# TLSR8258 register map
File version: 0.1
Registers are 8-bit, access not given, no defined reset value unless marked. A register's access mark holds for its fields unless they carry their own. Offsets are from the block's base; [hi:lo] are bit positions; {n}, {i} and the like mark numbered series.

## TIMER — Auto-generated from section 'timer'
Base 0x00800620
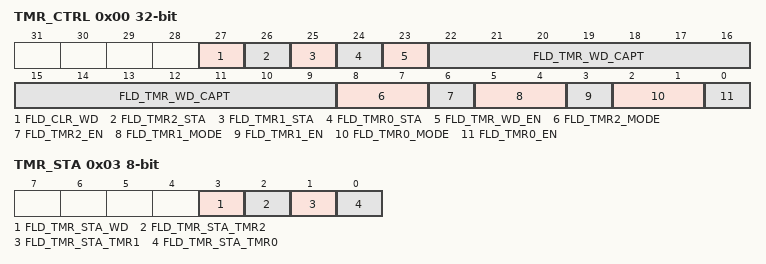
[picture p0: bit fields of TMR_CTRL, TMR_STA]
0x00 TMR_CTRL 32-bit — Auto-generated from tmr_ctrl; aliases: TMR_CTRL16, TMR_CTRL8
  [27] FLD_CLR_WD, [26] FLD_TMR2_STA, [25] FLD_TMR1_STA, [24] FLD_TMR0_STA, [23] FLD_TMR_WD_EN, [22:9] FLD_TMR_WD_CAPT, [8:7] FLD_TMR2_MODE, [6] FLD_TMR2_EN, [5:4] FLD_TMR1_MODE, [3] FLD_TMR1_EN, [2:1] FLD_TMR0_MODE, [0] FLD_TMR0_EN
0x03 TMR_STA — Auto-generated from tmr_sta
  [3] FLD_TMR_STA_WD, [2] FLD_TMR_STA_TMR2, [1] FLD_TMR_STA_TMR1, [0] FLD_TMR_STA_TMR0
{0x4+4i} TMR{i}_CAPT 32-bit (i=0..2) — Auto-generated from tmr{i}_capt
{0x10+4i} TMR{i}_TICK 32-bit (i=0..2) — Auto-generated from tmr{i}_tick

## IRQ — Auto-generated from section 'irq'
Base 0x00800640
0x00 IRQ_MASK 32-bit — Auto-generated from irq_mask
0x03 IRQ_EN — Auto-generated from irq_en
0x04 IRQ_PRI 32-bit — Auto-generated from irq_pri
0x08 IRQ_SRC 32-bit — Auto-generated from irq_src
  [31:24] FLD_IRQ_EN, [22] FLD_IRQ_GPIO_RISC1_EN, [21] FLD_IRQ_GPIO_RISC0_EN, [20] FLD_IRQ_SYSTEM_TIMER, [19] FLD_IRQ_PM_EN, [18] FLD_IRQ_GPIO_EN, [17] FLD_IRQ_USB_RST_EN, [16] FLD_IRQ_USB_250US_EN, [14] FLD_IRQ_SW_PWM_EN, [13] FLD_IRQ_ZB_RT_EN, [12] FLD_IRQ_EP_DATA_EN, [12] FLD_IRQ_IRQ4_EN, [11] FLD_IRQ_SET_INTF_EN, [10] FLD_IRQ_EP0_STA_EN, [9] FLD_IRQ_EP0_DAT_EN, [8] FLD_IRQ_EP0_SETUP_EN, [7] FLD_IRQ_HOST_CMD_EN, [7] FLD_IRQ_MIX_CMD_EN, [6] FLD_IRQ_UART_EN, [5] FLD_IRQ_DAM_FIFO_EN, [4] FLD_IRQ_DMA_EN, [3] FLD_IRQ_USB_PWDN_EN, [2] FLD_IRQ_TMR2_EN, [1] FLD_IRQ_TMR1_EN, [0] FLD_IRQ_TMR0_EN
0x0A IRQ_SRC3 — Auto-generated from irq_src3

## SYSTEM_TIMER — Auto-generated from section 'system timer'
Base 0x00800740
0x00 SYSTEM_TICK 32-bit — Auto-generated from system_tick
0x04 SYSTEM_TICK_IRQ 32-bit — Auto-generated from system_tick_irq
0x08 SYSTEM_WAKEUP_TICK 32-bit — Auto-generated from system_wakeup_tick
0x0C SYSTEM_TICK_MODE — Auto-generated from system_tick_mode
0x0F SYSTEM_TICK_CTRL — Auto-generated from system_tick_ctrl
  [1] FLD_SYSTEM_TICK_IRQ_EN, [1] FLD_SYSTEM_TICK_RUNNING, [1] FLD_SYSTEM_TICK_STOP, [0] FLD_SYSTEM_TICK_START

## PWM — Auto-generated from section 'pwm'
Base 0x00800780
0x00 PWM_ENABLE — Auto-generated from pwm_enable
0x01 PWM0_ENABLE — Auto-generated from pwm0_enable
0x02 PWM_CLK — Auto-generated from pwm_clk
0x03 PWM0_MODE — Auto-generated from pwm0_mode
0x04 PWM_INVERT — Auto-generated from pwm_invert
0x05 PWM_N_INVERT — Auto-generated from pwm_n_invert
0x06 PWM_POL — Auto-generated from pwm_pol
0x2C PWM0_PULSE_NUM 16-bit — Auto-generated from pwm0_pulse_num
0x30 PWM_IRQ_MASK — Auto-generated from pwm_irq_mask
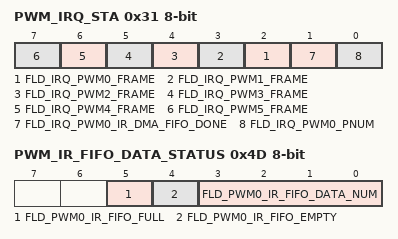
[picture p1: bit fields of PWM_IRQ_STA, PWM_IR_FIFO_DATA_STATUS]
0x31 PWM_IRQ_STA — Auto-generated from pwm_irq_sta
  [n+2] FLD_IRQ_PWM{n}_FRAME (n=0..5), [1] FLD_IRQ_PWM0_IR_DMA_FIFO_DONE, [0] FLD_IRQ_PWM0_PNUM
0x32 PWM0_FIFO_MODE_IRQ_MASK — Auto-generated from pwm0_fifo_mode_irq_mask
  [0] FLD_PWM0_IRQ_IR_FIFO_EN
0x33 PWM0_FIFO_MODE_IRQ_STA — Auto-generated from pwm0_fifo_mode_irq_sta
  [0] FLD_PWM0_IRQ_IR_FIFO_CNT
0x4C PWM_IR_FIFO_IRQ_TRIG_LEVEL — Auto-generated from pwm_ir_fifo_irq_trig_level
0x4D PWM_IR_FIFO_DATA_STATUS — Auto-generated from pwm_ir_fifo_data_status
  [5] FLD_PWM0_IR_FIFO_FULL, [4] FLD_PWM0_IR_FIFO_EMPTY, [3:0] FLD_PWM0_IR_FIFO_DATA_NUM
0x4E PWM_IR_CLR_FIFO_DATA — Auto-generated from pwm_ir_clr_fifo_data
  [0] FLD_PWM0_IR_FIFO_CLR_DATA

## FIFO — Auto-generated from section 'fifo'
Base 0x00800800
{0x0+0x100*i} FIFO{i}_DATA 32-bit (i=0..2) — Auto-generated from fifo{i}_data

## DFIFO — Auto-generated from section 'dfifo'
Base 0x00800B00
{0x0+4i} DFIFO{i}_ADDR 16-bit (i=0..2) — Auto-generated from dfifo{i}_addr
{0x2+4i} DFIFO{i}_SIZE (i=0..2) — Auto-generated from dfifo{i}_size
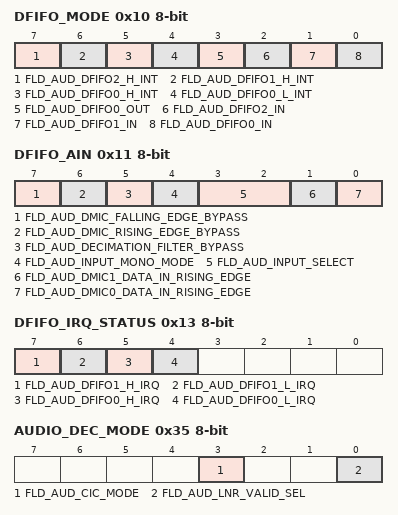
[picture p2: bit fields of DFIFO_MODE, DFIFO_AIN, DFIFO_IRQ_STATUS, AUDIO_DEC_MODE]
0x10 DFIFO_MODE — Auto-generated from dfifo_mode
  [7] FLD_AUD_DFIFO2_H_INT, [6] FLD_AUD_DFIFO1_H_INT, [5] FLD_AUD_DFIFO0_H_INT, [4] FLD_AUD_DFIFO0_L_INT, [3] FLD_AUD_DFIFO0_OUT, [2] FLD_AUD_DFIFO2_IN, [1] FLD_AUD_DFIFO1_IN, [0] FLD_AUD_DFIFO0_IN
0x11 DFIFO_AIN — Auto-generated from dfifo_ain
  [7] FLD_AUD_DMIC_FALLING_EDGE_BYPASS, [6] FLD_AUD_DMIC_RISING_EDGE_BYPASS, [5] FLD_AUD_DECIMATION_FILTER_BYPASS, [4] FLD_AUD_INPUT_MONO_MODE, [3:2] FLD_AUD_INPUT_SELECT, [1] FLD_AUD_DMIC1_DATA_IN_RISING_EDGE, [0] FLD_AUD_DMIC0_DATA_IN_RISING_EDGE
0x12 DFIFO_DEC_RATIO — Auto-generated from dfifo_dec_ratio
0x13 DFIFO_IRQ_STATUS — Auto-generated from dfifo_irq_status
  [7] FLD_AUD_DFIFO1_H_IRQ, [6] FLD_AUD_DFIFO1_L_IRQ, [5] FLD_AUD_DFIFO0_H_IRQ, [4] FLD_AUD_DFIFO0_L_IRQ
{0x14+4i} DFIFO{i}_RPTR 16-bit (i=0..2) — Auto-generated from dfifo{i}_rptr
{0x16+4i} DFIFO{i}_WPTR 16-bit (i=0..2) — Auto-generated from dfifo{i}_wptr
{0x20+4i} DFIFO{i}_NUM 16-bit (i=0..2) — Auto-generated from dfifo{i}_num
0x2C DFIFO0_MANUAL — Auto-generated from dfifo0_manual
  [0] FLD_DFIFO_MANUAL_MODE_EN
0x30 DFIFO0_MAN_DAT 32-bit — Auto-generated from dfifo0_man_dat
0x34 ALC_SFT — Auto-generated from alc_sft
0x35 AUDIO_DEC_MODE — Auto-generated from audio_dec_mode
  [3] FLD_AUD_CIC_MODE, [0] FLD_AUD_LNR_VALID_SEL
0x36 ADC_MUL — Auto-generated from adc_mul
0x37 ADC_BIAS — Auto-generated from adc_bias
0x40 AUD_ALC_HPF_LPF_CTRL — Auto-generated from aud_alc_hpf_lpf_ctrl
  [7] FLD_AUD_ALC_DIGITAL_MODE_AUTO_REGULATE_EN, [7] FLD_DOUBLE_DOWN_SAMPLING_ON, [6] FLD_AUD_IN_LPF_BYPASS, [5] FLD_AUD_IN_ALC_BYPASS, [4] FLD_AUD_IN_HPF_BYPASS, [6:0] FLD_AUD_ALC_MIN_PGA_IN_ANALOG_MODE, [5:0] FLD_AUD_ALC_MIN_VOLUME_IN_DIGITAL_MODE, [3:0] FLD_AUD_IN_HPF_SFT
0x43 ALC_VOL_H — Auto-generated from alc_vol_h
  [6:0] FLD_AUD_ALC_MAX_PGA_IN_ANALOG_MODE, [5:0] FLD_AUD_ALC_MAX_VOLUME_IN_DIGITAL_MODE
0x44 ALC_VOL_TH_H 16-bit — Auto-generated from alc_vol_th_h
0x46 ALC_VOL_TH_L 16-bit — Auto-generated from alc_vol_th_l
0x48 ALC_VOL_TH_N 16-bit — Auto-generated from alc_vol_th_n
0x4A ALC_VAD_TH_N 16-bit — Auto-generated from alc_vad_th_n
0x4C ALC_VOL_STEP — Auto-generated from alc_vol_step
0x4D ALC_VOL_L — Auto-generated from alc_vol_l
0x4E ALC_VOL_R — Auto-generated from alc_vol_r
0x50 ALC_PEAK_TICK 16-bit — Auto-generated from alc_peak_tick
0x52 ALC_DEC_TICK — Auto-generated from alc_dec_tick
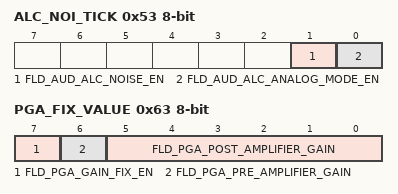
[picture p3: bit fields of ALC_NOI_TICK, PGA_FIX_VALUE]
0x53 ALC_NOI_TICK — Auto-generated from alc_noi_tick
  [1] FLD_AUD_ALC_NOISE_EN, [0] FLD_AUD_ALC_ANALOG_MODE_EN
0x55 ALC_COEF_IIR — Auto-generated from alc_coef_iir
0x56 ALC_DAT_MASK — Auto-generated from alc_dat_mask
0x57 ALC_INC_SPD — Auto-generated from alc_inc_spd
0x58 ALC_INC_MAX — Auto-generated from alc_inc_max
0x59 ALC_DEC_SPD — Auto-generated from alc_dec_spd
0x5A ALC_DEC_MAX — Auto-generated from alc_dec_max
0x5B ALC_NOI_SPD — Auto-generated from alc_noi_spd
0x5C ALC_NOI_MAX — Auto-generated from alc_noi_max
0x5D PGA_GAIN_INIT — Auto-generated from pga_gain_init
0x60 PGA_MAN_SPEED — Auto-generated from pga_man_speed
0x61 PGA_MAN_TARGET_L — Auto-generated from pga_man_target_l
0x62 PGA_VALUE_L — Auto-generated from pga_value_l
0x63 PGA_FIX_VALUE — Auto-generated from pga_fix_value
  [7] FLD_PGA_GAIN_FIX_EN, [6] FLD_PGA_PRE_AMPLIFIER_GAIN, [5:0] FLD_PGA_POST_AMPLIFIER_GAIN
0x64 PGA_R_L — Auto-generated from pga_r_l
0x65 PGA_MAN_TARGET_R — Auto-generated from pga_man_target_r
0x66 PGA_VALUE_R — Auto-generated from pga_value_r

## DMA — Auto-generated from section 'dma'
Base 0x00800C00
{0x0+4i} DMA{i}_ADDR 16-bit (i=0..5) — Auto-generated from dma{i}_addr
{0x2+4i} DMA{i}_SIZE (i=0..5) — Auto-generated from dma{i}_size
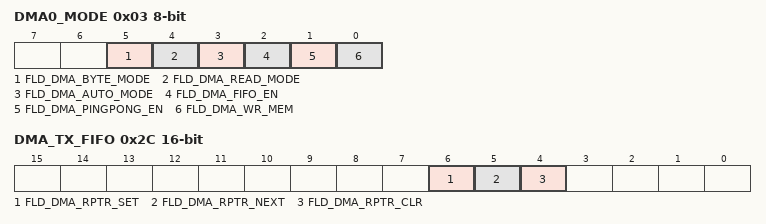
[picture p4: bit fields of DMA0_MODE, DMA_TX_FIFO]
0x03 DMA0_MODE — Auto-generated from dma0_mode
  [5] FLD_DMA_BYTE_MODE, [4] FLD_DMA_READ_MODE, [3] FLD_DMA_AUTO_MODE, [2] FLD_DMA_FIFO_EN, [1] FLD_DMA_PINGPONG_EN, [0] FLD_DMA_WR_MEM
{0x3+4i} DMA{i}_MODE (i=1..5) — Auto-generated from dma{i}_mode
0x18 DMA7_ADDR 16-bit — Auto-generated from dma7_addr
0x1A DMA7_SIZE — Auto-generated from dma7_size
0x1B DMA7_MODE — Auto-generated from dma7_mode
0x1C DMA_T_ADDR 16-bit — Auto-generated from dma_t_addr
0x1E DMA_T_SIZE — Auto-generated from dma_t_size
0x20 DMA_CHN_EN — Auto-generated from dma_chn_en
0x21 DMA_CHN_IRQ_MSK — Auto-generated from dma_chn_irq_msk
0x24 DMA_TX_RDY0 — Auto-generated from dma_tx_rdy0
0x25 DMA_TX_RDY1 — Auto-generated from dma_tx_rdy1
0x26 DMA_RX_RDY0 — Auto-generated from dma_rx_rdy0
0x27 DMA_RX_RDY1 — Auto-generated from dma_rx_rdy1
  [7] FLD_DMA_CHN7, [7] FLD_DMA_CHN_PWM, [n] FLD_DMA_CHN{n} (n=0..5), [5] FLD_DMA_CHN_AES_IN, [4] FLD_DMA_CHN_AES_OUT, [3] FLD_DMA_CHN_RF_TX, [2] FLD_DMA_CHN_RF_RX, [1] FLD_DMA_CHN_UART_TX, [0] FLD_DMA_CHN_UART_RX
0x28 DMA_RX_RPTR — Auto-generated from dma_rx_rptr
0x29 DMA_RX_WPTR — Auto-generated from dma_rx_wptr
0x2A DMA_TX_RPTR — Auto-generated from dma_tx_rptr
0x2B DMA_TX_WPTR — Auto-generated from dma_tx_wptr
0x2C DMA_TX_FIFO 16-bit — Auto-generated from dma_tx_fifo
  [6] FLD_DMA_RPTR_SET, [5] FLD_DMA_RPTR_NEXT, [4] FLD_DMA_RPTR_CLR
{0x40+i} DMA{i}_ADDRHI (i=0..5) — Auto-generated from dma{i}_addrhi
0x46 DMA_TA_ADDRHI — Auto-generated from dma_ta_addrhi
0x47 DMA_A3_ADDRHI — Auto-generated from dma_a3_addrhi
0x48 DMA7_ADDRHI — Auto-generated from dma7_addrhi

## LINKLAYER — Auto-generated from section 'linklayer'
Base 0x00800F02
0x00 RF_LL_CTRL_0 — Auto-generated from rf_ll_ctrl_0
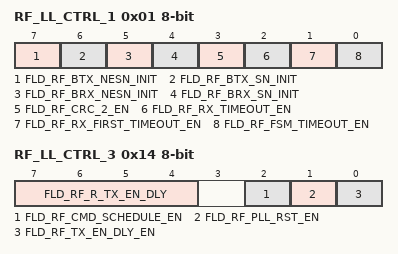
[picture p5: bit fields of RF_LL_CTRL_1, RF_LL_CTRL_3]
0x01 RF_LL_CTRL_1 — Auto-generated from rf_ll_ctrl_1
  [7] FLD_RF_BTX_NESN_INIT, [6] FLD_RF_BTX_SN_INIT, [5] FLD_RF_BRX_NESN_INIT, [4] FLD_RF_BRX_SN_INIT, [3] FLD_RF_CRC_2_EN, [2] FLD_RF_RX_TIMEOUT_EN, [1] FLD_RF_RX_FIRST_TIMEOUT_EN, [0] FLD_RF_FSM_TIMEOUT_EN
0x08 RF_RX_TIMEOUT 16-bit — Auto-generated from rf_rx_timeout
0x13 RF_LL_CTRL_2 — Auto-generated from rf_ll_ctrl_2
0x14 RF_LL_CTRL_3 — Auto-generated from rf_ll_ctrl_3
  [7:4] FLD_RF_R_TX_EN_DLY, [2] FLD_RF_CMD_SCHEDULE_EN, [1] FLD_RF_PLL_RST_EN, [0] FLD_RF_TX_EN_DLY_EN
0x1A RF_IRQ_MASK 16-bit — Auto-generated from rf_irq_mask
0x1E RF_IRQ_STATUS 16-bit — Auto-generated from rf_irq_status
0x2A RF_FSM_TIMEOUT 32-bit — Auto-generated from rf_fsm_timeout
  [12] FLD_RF_IRQ_STX_TIMEOUT, [11] FLD_RF_IRQ_INVALID_PID, [10] FLD_RF_IRQ_FIRST_TIMEOUT, [9] FLD_RF_IRQ_RX_DR, [8] FLD_RF_IRQ_TX_DS, [7] FLD_CLK_48M_TO_CAL_DIG_MAN_EN, [7] FLD_RF_IRQ_RETRY_HIT, [7] FLD_XO_CAP_OFF_ANA, [6] FLD_CLK_24M_TO_SAR_EN, [6] FLD_RF_IRQ_FSM_TIMEOUT, [6] FLD_RX_MI_SEL, [6] FLD_XO_MODE_ANA, [5] FLD_CLK_48M_TO_DIG_EN, [5] FLD_RF_IRQ_CMD_DONE, [5] FLD_TX_MI_SEL, [4] FLD_CLK_48M_TO_RX_EN, [4] FLD_PLL_BG_POWER_DOWN, [4] FLD_RF_IRQ_RX_CRC_2, [3] FLD_DCCC_DOUBLER_POWER_DOWN, [2] FLD_RF_IRQ_RX_TIMEOUT, [1] FLD_RF_IRQ_TX, [0] FLD_RF_IRQ_RX, [4:0] FLD_TX_PA_PWR_H, [5:0] FLD_XO_CDAC_ANA
